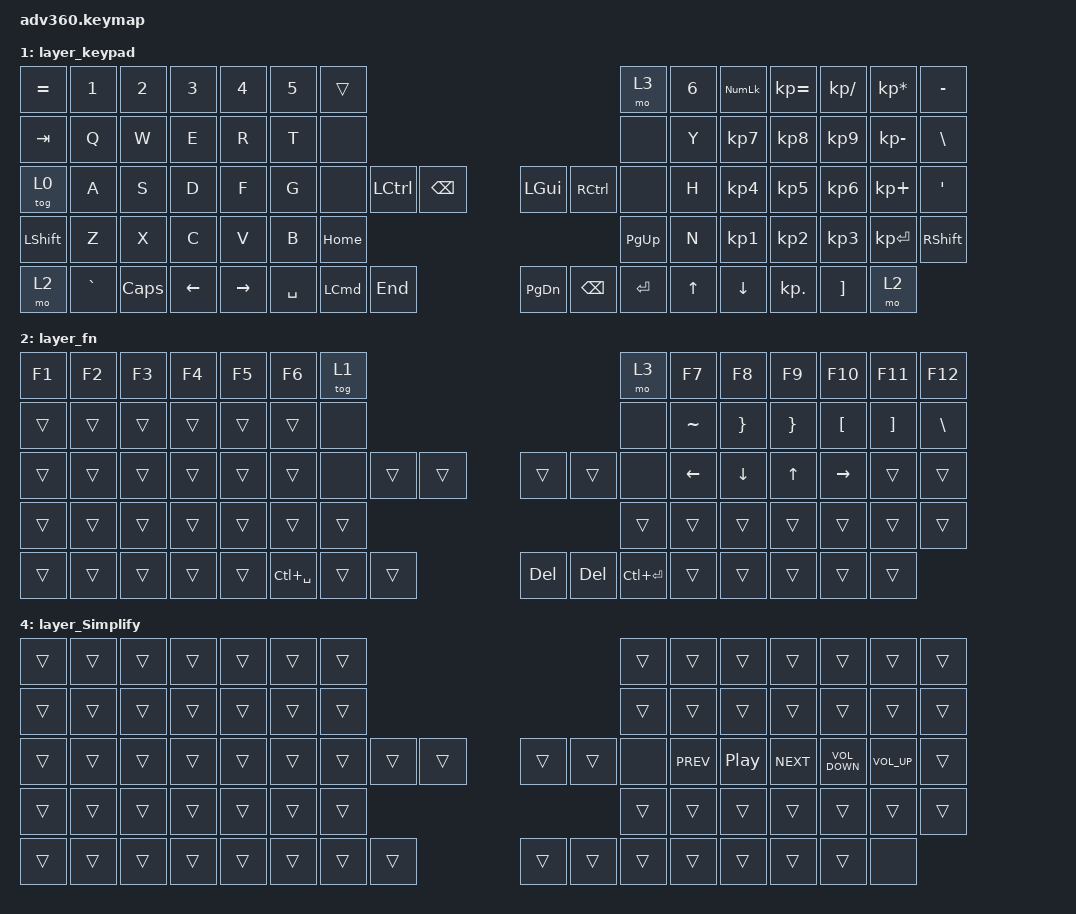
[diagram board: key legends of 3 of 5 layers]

/*
 * Copyright (c) 2020 The ZMK Contributors
 *
 * SPDX-License-Identifier: MIT
 */


/* THIS FILE WAS GENERATED!
 *
 * This file was generated automatically. You may or may not want to
 * edit it directly.
 */

#include <behaviors.dtsi>
#include <dt-bindings/zmk/keys.h>
#include <dt-bindings/zmk/bt.h>
#include <dt-bindings/zmk/rgb.h>
#include <dt-bindings/zmk/stp.h>
#include <dt-bindings/zmk/backlight.h>
#include <dt-bindings/zmk/pointing.h>

/ {
  behaviors {
    #include "macros.dtsi"
    #include "version.dtsi"

    hm: homerow_mods {
        compatible = "zmk,behavior-hold-tap";
        label = "HOMEROW_MODS";
        #binding-cells = <2>;
        tapping-term-ms = <200>;
        quick_tap_ms = <175>;
        flavor = "tap-preferred";
        bindings = <&kp>, <&kp>;
    };
    extra1 { 
      display-name = "Red";    
      status = "reserved";
    };

    extra2 { 
      display-name = "Purple";    
      status = "reserved";
    };

    extra3 { 
      display-name = "Cyan";    
      status = "reserved";
    };

    extra4 { 
      display-name = "Yellow";    
      status = "reserved";
    };
  };

    keymap {
        compatible = "zmk,keymap";


        default_layer {
            bindings = <
      &kp GRAVE            &kp N1      &kp N2    &kp N3    &kp N4  &kp N5               &tog 1                                                                              &mo 3  &kp N6     &kp N7     &kp N8      &kp N9             &kp N0         &kp MINUS
        &kp TAB             &kp Q       &kp W     &kp E     &kp R   &kp T                &none                                                                              &none   &kp Y      &kp U      &kp I       &kp O              &kp P         &kp EQUAL
   &hm CAPSLOCK ESCAPE      &kp A       &kp S     &kp D     &kp F   &kp G                &none      &kp LEFT_ALT  &kp BACKSPACE                  &kp RIGHT_ALT   &none      &none   &kp H      &kp J      &kp K       &kp L           &kp SEMI  &kp SINGLE_QUOTE
 &kp LEFT_SHIFT             &kp Z       &kp X     &kp C     &kp V   &kp B                                                 &mo 4                          &none                      &kp N      &kp M  &kp COMMA  &kp PERIOD          &kp SLASH   &kp RIGHT_SHIFT
          &mo 2  &kp LEFT_CONTROL  &kp LEFT_ALT  &kp LBKT  &kp RBKT                    &kp SPACE  &kp LEFT_COMMAND      &kp RCTRL                  &kp BACKSPACE   &kp LS(LC(LA(LEFT_COMMAND)))  &kp ENTER          &kp TILDE   &kp LBRC    &kp RIGHT_ALT  &kp RIGHT_CONTROL             &mo 2
            >;
        };

        layer_keypad {
            bindings = <
 &kp EQUAL     &kp N1    &kp N2    &kp N3     &kp N4  &kp N5               &trans                                                                                 &mo 3  &kp N6  &kp KP_NUM  &kp KP_EQUAL  &kp KP_DIVIDE  &kp KP_MULTIPLY  &kp MINUS
   &kp TAB      &kp Q     &kp W     &kp E      &kp R   &kp T                &none                                                                                 &none   &kp Y   &kp KP_N7     &kp KP_N8      &kp KP_N9     &kp KP_MINUS   &kp BSLH
    &tog 0      &kp A     &kp S     &kp D      &kp F   &kp G                &none         &kp LCTRL  &kp BACKSPACE                   &kp LGUI      &kp RCTRL      &none   &kp H   &kp KP_N4     &kp KP_N5      &kp KP_N6      &kp KP_PLUS    &kp SQT
 &kp LSHFT      &kp Z     &kp X     &kp C      &kp V   &kp B                                              &kp HOME                  &kp PG_UP                             &kp N   &kp KP_N1     &kp KP_N2      &kp KP_N3     &kp KP_ENTER  &kp RSHFT
     &mo 2  &kp GRAVE  &kp CAPS  &kp LEFT  &kp RIGHT                    &kp SPACE  &kp LEFT_COMMAND        &kp END                  &kp PG_DN  &kp BACKSPACE  &kp ENTER              &kp UP      &kp DOWN     &kp KP_DOT         &kp RBKT      &mo 2
            >;
        };

        layer_fn {
            bindings = <
 &kp F1  &kp F2  &kp F3  &kp F4  &kp F5  &kp F6                     &tog 1                                                                        &mo 3     &kp F7    &kp F8    &kp F9    &kp F10   &kp F11        &kp F12
 &trans  &trans  &trans  &trans  &trans  &trans                      &none                                                                        &none  &kp TILDE  &kp RBRC  &kp RBRC   &kp LBKT  &kp RBKT  &kp BACKSLASH
 &trans  &trans  &trans  &trans  &trans  &trans                      &none  &trans  &trans                   &trans      &trans                   &none   &kp LEFT  &kp DOWN    &kp UP  &kp RIGHT    &trans        &trans
 &trans  &trans  &trans  &trans  &trans  &trans                                     &trans                   &trans                                         &trans    &trans    &trans     &trans    &trans        &trans
 &trans  &trans  &trans  &trans  &trans                    &kp LC(SPACE)  &trans  &trans                  &kp DEL  &kp DELETE  &kp LC(ENTER)               &trans    &trans     &trans    &trans         &trans
            >;
        };

        layer_mod {
            bindings = <
  &none  &bt BT_SEL 0  &bt BT_SEL 1  &bt BT_SEL 2     &bt BT_SEL 3  &bt BT_SEL 4                             &none                                                                                   &trans  &bt BT_SEL 0  &bt BT_SEL 1  &bt BT_SEL 2  &bt BT_SEL 3  &bt BT_SEL 4   &none
  &none         &none         &none         &none            &none         &none                       &bootloader                                                                              &bootloader         &none         &none         &none         &none         &none   &none
  &none         &none         &none         &none            &none         &none            &rgb_ug RGB_MEFS_CMD 5  &bt BT_CLR  &bt BT_CLR                  &bt BT_CLR  &rgb_ug RGB_MEFS_CMD 5        &none         &none         &none         &none         &none         &none   &none
  &none         &none         &none         &none            &none         &none                                                     &none                       &none                                              &none         &none         &none         &none         &none   &none
  &none         &none    &bl BL_INC    &bl BL_DEC  &rgb_ug RGB_TOG                                      &bl BL_TOG       &none       &none                  &bl BL_TOG         &rgb_ug RGB_TOG   &bl BL_INC                  &bl BL_DEC         &none         &none         &none
            >;
        };

        layer_Simplify {
            bindings = <
 &trans  &trans  &trans  &trans  &trans  &trans            &trans                                                  &trans      &trans    &trans      &trans             &trans        &trans  &trans
 &trans  &trans  &trans  &trans  &trans  &trans            &trans                                                  &trans      &trans    &trans      &trans             &trans        &trans  &trans
 &trans  &trans  &trans  &trans  &trans  &trans            &trans  &trans  &trans                  &trans  &trans   &none  &kp C_PREV  &kp C_PP  &kp C_NEXT  &kp C_VOLUME_DOWN  &kp C_VOL_UP  &trans
 &trans  &trans  &trans  &trans  &trans  &trans                            &trans                  &trans                      &trans    &trans      &trans             &trans        &trans  &trans
 &trans  &trans  &trans  &trans  &trans                    &trans  &trans  &trans                  &trans  &trans  &trans                &trans      &trans             &trans        &trans   &none
            >;
        };

    };
};
